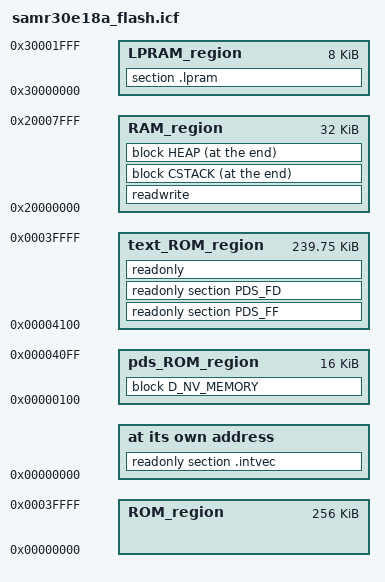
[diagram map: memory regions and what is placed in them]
/**
 * \file
 *
 * \brief Linker script for running in internal FLASH on the SAML21E18A
 *
 * Copyright (c) 2018 Microchip Technology Inc. and its subsidiaries. 
 *
 * \asf_license_start
 *
 * \page License
 *
 * Subject to your compliance with these terms, you may use Microchip
 * software and any derivatives exclusively with Microchip products. 
 * It is your responsibility to comply with third party license terms applicable 
 * to your use of third party software (including open source software) that 
 * may accompany Microchip software.
 *
 * THIS SOFTWARE IS SUPPLIED BY MICROCHIP "AS IS".  NO WARRANTIES, 
 * WHETHER EXPRESS, IMPLIED OR STATUTORY, APPLY TO THIS SOFTWARE, 
 * INCLUDING ANY IMPLIED WARRANTIES OF NON-INFRINGEMENT, MERCHANTABILITY, 
 * AND FITNESS FOR A PARTICULAR PURPOSE. IN NO EVENT WILL MICROCHIP BE 
 * LIABLE FOR ANY INDIRECT, SPECIAL, PUNITIVE, INCIDENTAL OR CONSEQUENTIAL 
 * LOSS, DAMAGE, COST OR EXPENSE OF ANY KIND WHATSOEVER RELATED TO THE 
 * SOFTWARE, HOWEVER CAUSED, EVEN IF MICROCHIP HAS BEEN ADVISED OF THE 
 * POSSIBILITY OR THE DAMAGES ARE FORESEEABLE.  TO THE FULLEST EXTENT 
 * ALLOWED BY LAW, MICROCHIP'S TOTAL LIABILITY ON ALL CLAIMS IN ANY WAY 
 * RELATED TO THIS SOFTWARE WILL NOT EXCEED THE AMOUNT OF FEES, IF ANY, 
 * THAT YOU HAVE PAID DIRECTLY TO MICROCHIP FOR THIS SOFTWARE.
 *
 * \asf_license_stop
 *
 */
/*
 * Support and FAQ: visit <a href="https://www.microchip.com/support/">Microchip Support</a>
*/

/*###ICF### Section handled by ICF editor, don't touch! ****/
/*-Editor annotation file-*/
/* IcfEditorFile="$TOOLKIT_DIR$\config\ide\IcfEditor\cortex_v1_0.xml" */
/*-Specials-*/
define symbol __ICFEDIT_intvec_start__        = 0x00000000;
/*-Memory Regions-*/
define symbol __ICFEDIT_region_RAM_start__    = 0x20000000;
define symbol __ICFEDIT_region_RAM_end__      = 0x20007FFF;
define symbol __ICFEDIT_region_LPRAM_start__  = 0x30000000;
define symbol __ICFEDIT_region_LPRAM_end__    = 0x30001FFF;
define symbol __ICFEDIT_region_ROM_start__    = 0x00000000;
define symbol __ICFEDIT_region_ROM_end__      = 0x0003FFFF;
define symbol __ICFEDIT_region_pds_ROM_start__  = 0x00000100;
define symbol __ICFEDIT_region_pds_ROM_end__    = 0x00040FF;
define symbol __ICFEDIT_region_text_ROM_start__  = 0x004100;
define symbol __ICFEDIT_region_text_ROM_end__    = 0x0003FFFF;

/*-Sizes-*/
if (!isdefinedsymbol(__ICFEDIT_size_cstack__)) {
  define symbol __ICFEDIT_size_cstack__    = 0x2000;
}
if (!isdefinedsymbol(__ICFEDIT_size_heap__)) {
  define symbol __ICFEDIT_size_heap__      = 0x0;
}
define symbol D_NV_MEMORY_START = 0x400;
define symbol _D_NV_MEMORY_SIZE = 0x4000;
/**** End of ICF editor section. ###ICF###*/

define memory mem with size = 4G;
define region RAM_region    = mem:[from __ICFEDIT_region_RAM_start__ to __ICFEDIT_region_RAM_end__];
define region LPRAM_region  = mem:[from __ICFEDIT_region_LPRAM_start__ to __ICFEDIT_region_LPRAM_end__];
define region ROM_region    = mem:[from __ICFEDIT_region_ROM_start__ to __ICFEDIT_region_ROM_end__];
define region pds_ROM_region        = mem:[from __ICFEDIT_region_pds_ROM_start__ to __ICFEDIT_region_pds_ROM_end__];
define region text_ROM_region       = mem:[from __ICFEDIT_region_text_ROM_start__ to __ICFEDIT_region_text_ROM_end__];

define block CSTACK with alignment = 8, size = __ICFEDIT_size_cstack__ { };
define block HEAP   with alignment = 8, size = __ICFEDIT_size_heap__   { };
define block D_NV_MEMORY with size = _D_NV_MEMORY_SIZE, alignment = 8 { };

initialize by copy { readwrite };
do not initialize  { section .noinit };

place at address mem:__ICFEDIT_intvec_start__ { readonly section .intvec };
place in text_ROM_region          { readonly section PDS_FF};    /* PDS files descriptors segment */
place in text_ROM_region          { readonly section PDS_FD};    /* PDS directories descriptors segment */
place in pds_ROM_region           { block D_NV_MEMORY };
place in text_ROM_region          { readonly };
place in RAM_region                           { readwrite };
place at end of RAM_region                    { block CSTACK, block HEAP };
place in LPRAM_region                         { section .lpram };
